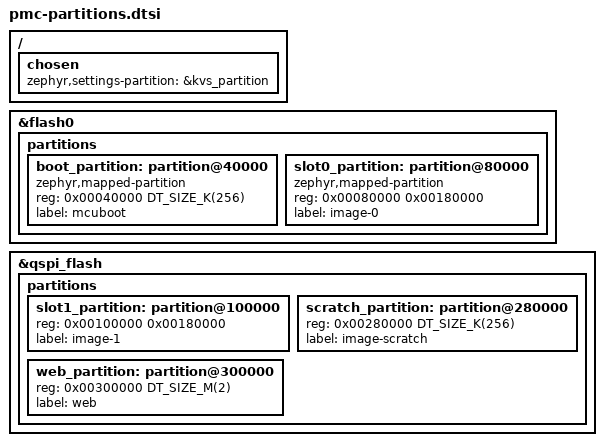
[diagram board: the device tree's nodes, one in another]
/*
 * Flash map for the Portenta Machine Control Explorer, included by BOTH
 * MCUboot and the application.
 *
 * SPDX-License-Identifier: Apache-2.0
 * Copyright (c) 2026 Noah Christian
 *
 * Every number here is explained in docs/FLASH.md, partition by partition.
 * The short version:
 *
 *   0x08000000  256K  Arduino DFU bootloader   never declared, never written
 *   0x08040000  256K  boot_partition, MCUboot  chainloaded from above
 *   0x08080000 1536K  slot0, the running image
 *   QSPI 0x100000  1536K  slot1    exactly equal to slot0
 *   QSPI 0x280000   256K  scratch  2x the internal sector, not equal to it
 *   QSPI 0x300000     2M  web      LittleFS
 *
 * TWO THINGS THAT WILL BITE, both with the full reasoning in docs/FLASH.md:
 *
 *   - do NOT override flash0's size. Setting it to the real 2 MB looks
 *     obviously right and silently corrupts every write above 1 MB.
 *     tools/pre-commit refuses a commit that adds one.
 *   - if MCUboot and the application ever disagree about where a slot begins,
 *     nothing fails loudly. That is why there is one file and not two.
 */

/ {
	chosen {
		/* NVS, in the Arduino table's kvs partition - outside both image
		 * slots, so credentials survive every update. */
		zephyr,settings-partition = &kvs_partition;
	};
};

/*
 * All four of the board's internal partitions go, plus Arduino's 5 MB QSPI
 * ota region. The board's scratch sits at 0x08010000, sharing erase sector 0
 * with the bootloader, and a 128 KB-sector scratch cannot serve a 4 KB-sector
 * secondary slot - so neither could simply be resized.
 */
/delete-node/ &boot_partition;
/delete-node/ &slot0_partition;
/delete-node/ &slot1_partition;
/delete-node/ &scratch_partition;
/delete-node/ &ota_partition;

&flash0 {
	partitions {
		/* 2 sectors, so nothing shares an erase unit with the
		 * bootloader. Not read-only: that would only stop the
		 * application writing it, which it never does. */
		boot_partition: partition@40000 {
			compatible = "zephyr,mapped-partition";
			reg = <0x00040000 DT_SIZE_K(256)>;
			label = "mcuboot";
		};

		/* Sectors 4 to 15, ending at the top of flash. Crosses the 1 MB
		 * bank boundary deliberately, so the FIRST OTA exercises the
		 * bank-2 write trap rather than the fortieth. */
		slot0_partition: partition@80000 {
			compatible = "zephyr,mapped-partition";
			reg = <0x00080000 0x00180000>;
			label = "image-0";
		};
	};
};

&qspi_flash {
	partitions {
		/* Exactly equal to slot0: MCUboot swaps between equal slots. */
		slot1_partition: partition@100000 {
			reg = <0x00100000 0x00180000>;
			label = "image-1";
		};

		/* 256 KB = TWICE the 128 KB internal sector, not equal to it.
		 * An equal scratch passes boot_slots_compatible() and then
		 * fails during the swap. */
		scratch_partition: partition@280000 {
			reg = <0x00280000 DT_SIZE_K(256)>;
			label = "image-scratch";
		};

		/* 0x2c0000 to 0x300000 is 256 KB of spare, left unnamed. */

		/* LittleFS: the board image and the generated pages. 4 KB
		 * sectors make a filesystem cheap here; 128 KB ones would not. */
		web_partition: partition@300000 {
			reg = <0x00300000 DT_SIZE_M(2)>;
			label = "web";
		};
	};
};
